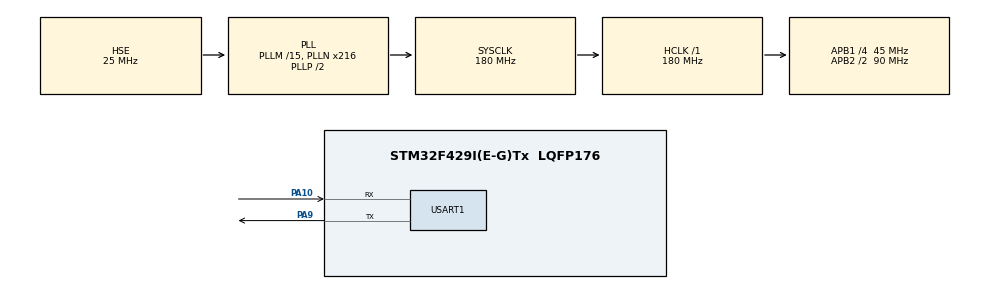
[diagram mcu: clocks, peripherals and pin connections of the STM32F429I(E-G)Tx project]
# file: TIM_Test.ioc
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Dma.Request0=USART1_RX
Dma.Request1=USART1_TX
Dma.USART1_RX.0.Direction=DMA_PERIPH_TO_MEMORY
Dma.USART1_RX.0.FIFOMode=DMA_FIFOMODE_DISABLE
Dma.USART1_RX.0.Instance=DMA2_Stream2
Dma.USART1_RX.0.MemDataAlignment=DMA_MDATAALIGN_BYTE
Dma.USART1_RX.0.MemInc=DMA_MINC_ENABLE
Dma.USART1_RX.0.Mode=DMA_NORMAL
Dma.USART1_RX.0.PeriphDataAlignment=DMA_PDATAALIGN_BYTE
Dma.USART1_RX.0.PeriphInc=DMA_PINC_DISABLE
Dma.USART1_RX.0.Priority=DMA_PRIORITY_LOW
Dma.USART1_TX.1.Direction=DMA_MEMORY_TO_PERIPH
Dma.USART1_TX.1.FIFOMode=DMA_FIFOMODE_DISABLE
Dma.USART1_TX.1.Instance=DMA2_Stream7
Dma.USART1_TX.1.MemDataAlignment=DMA_MDATAALIGN_BYTE
Dma.USART1_TX.1.MemInc=DMA_MINC_ENABLE
Dma.USART1_TX.1.Mode=DMA_NORMAL
Dma.USART1_TX.1.PeriphDataAlignment=DMA_PDATAALIGN_BYTE
Dma.USART1_TX.1.PeriphInc=DMA_PINC_DISABLE
Dma.USART1_TX.1.Priority=DMA_PRIORITY_LOW
Mcu.Family=STM32F4
Mcu.Name=STM32F429I(E-G)Tx
Mcu.Package=LQFP176
NVIC.DMA2_Stream2_IRQn=true\:0\:0\:false\:false\:true\:false\:true\:true
NVIC.DMA2_Stream7_IRQn=true\:0\:0\:false\:false\:true\:false\:true\:true
NVIC.PriorityGroup=NVIC_PRIORITYGROUP_4
NVIC.TIM6_DAC_IRQn=true\:0\:0\:false\:false\:true\:true\:true\:true
NVIC.USART1_IRQn=true\:0\:0\:false\:false\:true\:false\:true\:true
PA10.Mode=Asynchronous
PA10.Signal=USART1_RX
PA9.Mode=Asynchronous
PA9.Signal=USART1_TX
PH0/OSC_IN.Mode=HSE-External-Oscillator
PH0/OSC_IN.Signal=RCC_OSC_IN
PH1/OSC_OUT.Mode=HSE-External-Oscillator
PH1/OSC_OUT.Signal=RCC_OSC_OUT
ProjectManager.HeapSize=0x200
ProjectManager.StackSize=0x400
ProjectManager.TargetToolchain=MDK-ARM V5.32
RCC.48MHZClocksFreq_Value=90000000
RCC.AHBFreq_Value=180000000
RCC.APB1CLKDivider=RCC_HCLK_DIV4
RCC.APB1Freq_Value=45000000
RCC.APB1TimFreq_Value=90000000
RCC.APB2CLKDivider=RCC_HCLK_DIV2
RCC.APB2Freq_Value=90000000
RCC.APB2TimFreq_Value=180000000
RCC.CortexFreq_Value=180000000
RCC.HCLKFreq_Value=180000000
RCC.HSE_VALUE=25000000
RCC.HSI_VALUE=16000000
RCC.LSE_VALUE=32768
RCC.PLLM=15
RCC.PLLN=216
RCC.PLLSourceVirtual=RCC_PLLSOURCE_HSE
RCC.SYSCLKFreq_VALUE=180000000
RCC.SYSCLKSource=RCC_SYSCLKSOURCE_PLLCLK
RCC.VCOOutputFreq_Value=360000000
TIM6.Period=9999
TIM6.Prescaler=8999
USART1.VirtualMode=VM_ASYNC
VP_TIM6_VS_ClockSourceINT.Mode=Enable_Timer
board=custom

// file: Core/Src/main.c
/* USER CODE BEGIN Header */
/**
 ******************************************************************************
 * @file           : main.c
 * @brief          : Main program body
 ******************************************************************************
 * @attention
 *
 * Copyright (c) 2026 STMicroelectronics.
 * All rights reserved.
 *
 * This software is licensed under terms that can be found in the LICENSE file
 * in the root directory of this software component.
 * If no LICENSE file comes with this software, it is provided AS-IS.
 *
 ******************************************************************************
 */
/* USER CODE END Header */
#include "main.h"
#include <stdio.h>

TIM_HandleTypeDef htim6;

UART_HandleTypeDef huart1;
DMA_HandleTypeDef hdma_usart1_rx;
DMA_HandleTypeDef hdma_usart1_tx;

/* USER CODE BEGIN PV */
volatile uint32_t tick = 0; /* 定时器中断次数 */
volatile uint32_t interval = 0;
uint32_t last_ms = 0;

/* USER CODE END PV */

void SystemClock_Config(void);
static void MX_GPIO_Init(void);
static void MX_DMA_Init(void);
static void MX_USART1_UART_Init(void);
static void MX_TIM6_Init(void);

int main(void) {

    /* USER CODE BEGIN 1 */
    uint32_t last_tick = 0;
    char buf[64];

    /* USER CODE END 1 */

    /* MCU Configuration--------------------------------------------------------*/

    /* Reset of all peripherals, Initializes the Flash interface and the Systick. */
    HAL_Init();

    /* Configure the system clock */
    SystemClock_Config();

    /* Initialize all configured peripherals */
    MX_GPIO_Init();
    MX_DMA_Init();
    MX_USART1_UART_Init();
    MX_TIM6_Init();
    /* USER CODE BEGIN 2 */
    HAL_TIM_Base_Start_IT(&htim6); /* 启动定时器中断 */

    /* USER CODE END 2 */

    /* Infinite loop */
    while (1) {

        /* USER CODE BEGIN 3 */
        if (tick != last_tick) {
            last_tick = tick;

            /* 把数字格式化成字符串 */
            int n = sprintf(buf, "tick=%lu  interval=%lu\r\n",
                            (unsigned long)tick, (unsigned long)interval);

            HAL_UART_Transmit(&huart1, (uint8_t *)buf, n, 100);
        }
    }
    /* USER CODE END 3 */
}

void SystemClock_Config(void) {
    RCC_OscInitTypeDef RCC_OscInitStruct = {0};
    RCC_ClkInitTypeDef RCC_ClkInitStruct = {0};

    /** Configure the main internal regulator output voltage
     */
    __HAL_RCC_PWR_CLK_ENABLE();
    __HAL_PWR_VOLTAGESCALING_CONFIG(PWR_REGULATOR_VOLTAGE_SCALE1);

    /** Initializes the RCC Oscillators according to the specified parameters
     * in the RCC_OscInitTypeDef structure.
     */
    RCC_OscInitStruct.OscillatorType = RCC_OSCILLATORTYPE_HSE;
    RCC_OscInitStruct.HSEState = RCC_HSE_ON;
    RCC_OscInitStruct.PLL.PLLState = RCC_PLL_ON;
    RCC_OscInitStruct.PLL.PLLSource = RCC_PLLSOURCE_HSE;
    RCC_OscInitStruct.PLL.PLLM = 15;
    RCC_OscInitStruct.PLL.PLLN = 216;
    RCC_OscInitStruct.PLL.PLLP = RCC_PLLP_DIV2;
    RCC_OscInitStruct.PLL.PLLQ = 4;
    if (HAL_RCC_OscConfig(&RCC_OscInitStruct) != HAL_OK) {
        Error_Handler();
    }

    /** Activate the Over-Drive mode
     */
    if (HAL_PWREx_EnableOverDrive() != HAL_OK) {
        Error_Handler();
    }

    /** Initializes the CPU, AHB and APB buses clocks
     */
    RCC_ClkInitStruct.ClockType = RCC_CLOCKTYPE_HCLK | RCC_CLOCKTYPE_SYSCLK | RCC_CLOCKTYPE_PCLK1 | RCC_CLOCKTYPE_PCLK2;
    RCC_ClkInitStruct.SYSCLKSource = RCC_SYSCLKSOURCE_PLLCLK;
    RCC_ClkInitStruct.AHBCLKDivider = RCC_SYSCLK_DIV1;
    RCC_ClkInitStruct.APB1CLKDivider = RCC_HCLK_DIV4;
    RCC_ClkInitStruct.APB2CLKDivider = RCC_HCLK_DIV2;

    if (HAL_RCC_ClockConfig(&RCC_ClkInitStruct, FLASH_LATENCY_5) != HAL_OK) {
        Error_Handler();
    }
}

static void MX_TIM6_Init(void) {

    TIM_MasterConfigTypeDef sMasterConfig = {0};

    htim6.Instance = TIM6;
    htim6.Init.Prescaler = 8999;
    htim6.Init.CounterMode = TIM_COUNTERMODE_UP;
    htim6.Init.Period = 9999;
    htim6.Init.AutoReloadPreload = TIM_AUTORELOAD_PRELOAD_DISABLE;
    if (HAL_TIM_Base_Init(&htim6) != HAL_OK) {
        Error_Handler();
    }
    sMasterConfig.MasterOutputTrigger = TIM_TRGO_RESET;
    sMasterConfig.MasterSlaveMode = TIM_MASTERSLAVEMODE_DISABLE;
    if (HAL_TIMEx_MasterConfigSynchronization(&htim6, &sMasterConfig) != HAL_OK) {
        Error_Handler();
    }
}

static void MX_USART1_UART_Init(void) {

    huart1.Instance = USART1;
    huart1.Init.BaudRate = 115200;
    huart1.Init.WordLength = UART_WORDLENGTH_8B;
    huart1.Init.StopBits = UART_STOPBITS_1;
    huart1.Init.Parity = UART_PARITY_NONE;
    huart1.Init.Mode = UART_MODE_TX_RX;
    huart1.Init.HwFlowCtl = UART_HWCONTROL_NONE;
    huart1.Init.OverSampling = UART_OVERSAMPLING_16;
    if (HAL_UART_Init(&huart1) != HAL_OK) {
        Error_Handler();
    }
}

static void MX_DMA_Init(void) {

    /* DMA controller clock enable */
    __HAL_RCC_DMA2_CLK_ENABLE();

    /* DMA interrupt init */
    /* DMA2_Stream2_IRQn interrupt configuration */
    HAL_NVIC_SetPriority(DMA2_Stream2_IRQn, 0, 0);
    HAL_NVIC_EnableIRQ(DMA2_Stream2_IRQn);
    /* DMA2_Stream7_IRQn interrupt configuration */
    HAL_NVIC_SetPriority(DMA2_Stream7_IRQn, 0, 0);
    HAL_NVIC_EnableIRQ(DMA2_Stream7_IRQn);
}

static void MX_GPIO_Init(void) {

    /* GPIO Ports Clock Enable */
    __HAL_RCC_GPIOH_CLK_ENABLE();
    __HAL_RCC_GPIOA_CLK_ENABLE();

}

/* USER CODE BEGIN 4 */
void HAL_TIM_PeriodElapsedCallback(TIM_HandleTypeDef *htim) {
    if (htim->Instance == TIM6) {
        tick++;
        interval = HAL_GetTick() - last_ms; /* 距上次中断过了多少 ms */
        last_ms = HAL_GetTick();
    }
}

/* USER CODE END 4 */

void Error_Handler(void) {
    __disable_irq();
    while (1) {
    }
}
